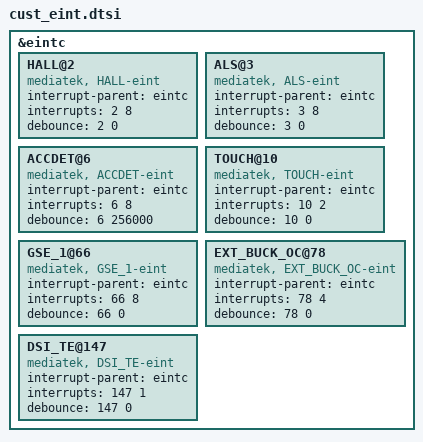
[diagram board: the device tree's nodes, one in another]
/*
 * Generated by MTK SP DrvGen Version 03.13.6 for MT6735. Copyright MediaTek Inc. (C) 2013.
 * Fri Dec 02 17:26:34 2016
 * Do Not Modify the File.
 */

/*************************
 * EINT DTSI File
*************************/

&eintc {
	HALL@2 {
		compatible = "mediatek, HALL-eint";
		interrupt-parent = <&eintc>;
		interrupts = <2 8>;
		debounce = <2 0>;
	};

	ALS@3 {
		compatible = "mediatek, ALS-eint";
		interrupt-parent = <&eintc>;
		interrupts = <3 8>;
		debounce = <3 0>;
	};

	ACCDET@6 {
		compatible = "mediatek, ACCDET-eint";
		interrupt-parent = <&eintc>;
		interrupts = <6 8>;
		debounce = <6 256000>;
	};

	TOUCH@10 {
		compatible = "mediatek, TOUCH-eint";
		interrupt-parent = <&eintc>;
		interrupts = <10 2>;
		debounce = <10 0>;
	};

	GSE_1@66 {
		compatible = "mediatek, GSE_1-eint";
		interrupt-parent = <&eintc>;
		interrupts = <66 8>;
		debounce = <66 0>;
	};

	EXT_BUCK_OC@78 {
		compatible = "mediatek, EXT_BUCK_OC-eint";
		interrupt-parent = <&eintc>;
		interrupts = <78 4>;
		debounce = <78 0>;
	};

	DSI_TE@147 {
		compatible = "mediatek, DSI_TE-eint";
		interrupt-parent = <&eintc>;
		interrupts = <147 1>;
		debounce = <147 0>;
	};

};
